# R7FA4E2B9 register map
Vendor: Renesas Electronics Corporation; Series: RA4; File version: 1.30.00
CPU: CM33 r0p4, little endian, MPU, FPU, VTOR, 4 interrupt priority bits, 96 interrupts
Registers are 32-bit, read-write, reset 0x0 unless marked. A register's access mark holds for its fields unless they carry their own. Offsets are from the block's base; [hi:lo] are bit positions; {n}, {i} and the like mark numbered series.

## USBFS — USB 2.0 Full,Speed Module
Base 0x40090000
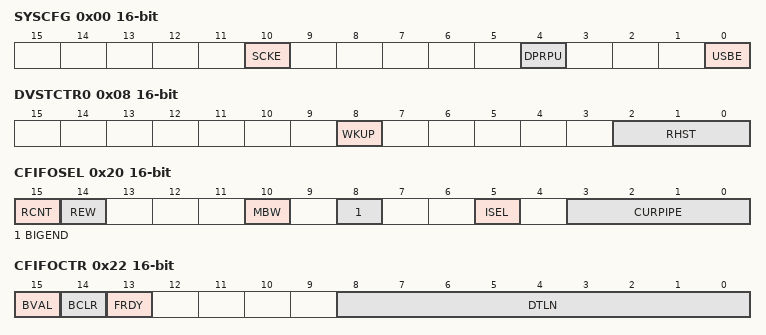
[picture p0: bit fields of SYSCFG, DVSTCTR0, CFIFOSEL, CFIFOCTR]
0x00 SYSCFG 16-bit — System Configuration Control Register
  [10] SCKE — USB Clock Enable
  [4] DPRPU — D+ Line Resistor Control
  [0] USBE — USBFS Operation Enable
0x04 SYSSTS0 16-bit ro — System Configuration Status Register 0
  [1:0] LNST — USB Data Line Status Monitor
0x08 DVSTCTR0 16-bit — Device State Control Register 0
  [8] WKUP — Wakeup Output
  [2:0] RHST ro — USB Bus Reset Status
0x14 CFIFO 16-bit — CFIFO Port Register
  [15:0] FIFOPORT
0x14 CFIFOL 8-bit (alternate view of CFIFO) — CFIFO Port Register
  [7:0] FIFOPORT
0x20 CFIFOSEL 16-bit — CFIFO Port Select Register
  [15] RCNT — Read Count Mode
  [14] REW wo — Buffer Pointer Rewind
  [10] MBW — CFIFO Port Access Bit Width
  [8] BIGEND — CFIFO Port Endian Control
  [5] ISEL — CFIFO Port Access Direction When DCP Is Selected
  [3:0] CURPIPE — CFIFO Port Access Pipe Specification
0x22 CFIFOCTR 16-bit — CFIFO Port Control Register
  [15] BVAL — Buffer Memory Valid Flag
  [14] BCLR wo — CPU Buffer Clear
  [13] FRDY ro — FIFO Port Ready
  [8:0] DTLN ro — Receive Data Length
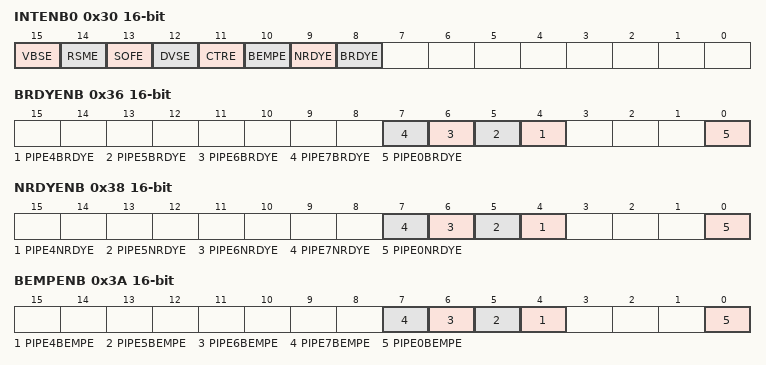
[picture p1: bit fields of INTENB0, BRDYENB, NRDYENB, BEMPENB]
0x30 INTENB0 16-bit — Interrupt Enable Register 0
  [15] VBSE — VBUS Interrupt Enable
  [14] RSME — Resume Interrupt Enable
  [13] SOFE — Frame Number Update Interrupt Enable
  [12] DVSE — Device State Transition Interrupt Enable
  [11] CTRE — Control Transfer Stage Transition Interrupt Enable
  [10] BEMPE — Buffer Empty Interrupt Enable
  [9] NRDYE — Buffer Not Ready Response Interrupt Enable
  [8] BRDYE — Buffer Ready Interrupt Enable
0x36 BRDYENB 16-bit — BRDY Interrupt Enable Register
  [n] PIPE{n}BRDYE (n=4..7) — BRDY Interrupt Enable for Pipe {n}
  [0] PIPE0BRDYE — BRDY Interrupt Enable for Pipe 0
0x38 NRDYENB 16-bit — NRDY Interrupt Enable Register
  [n] PIPE{n}NRDYE (n=4..7) — NRDY Interrupt Enable for Pipe {n}
  [0] PIPE0NRDYE — NRDY Interrupt Enable for Pipe 0
0x3A BEMPENB 16-bit — BEMP Interrupt Enable Register
  [n] PIPE{n}BEMPE (n=4..7) — BEMP Interrupt Enable for Pipe {n}
  [0] PIPE0BEMPE — BEMP Interrupt Enable for Pipe 0
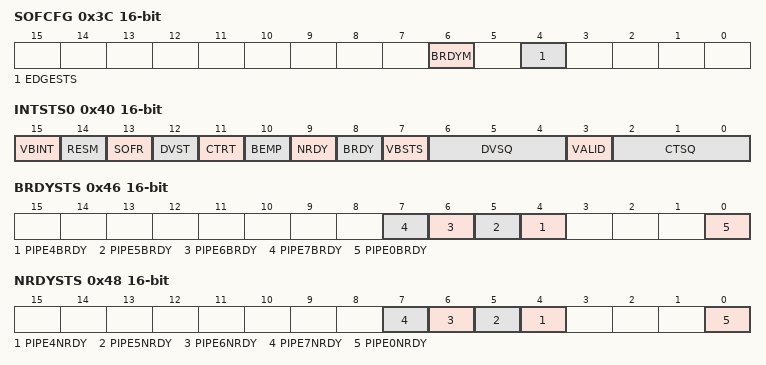
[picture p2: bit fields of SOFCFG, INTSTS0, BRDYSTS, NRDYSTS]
0x3C SOFCFG 16-bit — SOF Output Configuration Register
  [6] BRDYM — BRDY Interrupt Status Clear Timing
  [4] EDGESTS ro — Edge Interrupt Output Status Monitor
0x40 INTSTS0 16-bit (reset mask 0xEF6F) — Interrupt Status Register 0
  [15] VBINT — VBUS Interrupt Status
  [14] RESM — Resume Interrupt Status
  [13] SOFR — Frame Number Refresh Interrupt Status
  [12] DVST — Device State Transition Interrupt Status
  [11] CTRT — Control Transfer Stage Transition Interrupt Status
  [10] BEMP ro — Buffer Empty Interrupt Status
  [9] NRDY ro — Buffer Not Ready Interrupt Status
  [8] BRDY ro — Buffer Ready Interrupt Status
  [7] VBSTS ro — VBUS Input Status
  [6:4] DVSQ ro — Device State
  [3] VALID — USB Request Reception
  [2:0] CTSQ ro — Control Transfer Stage
0x46 BRDYSTS 16-bit — BRDY Interrupt Status Register
  [n] PIPE{n}BRDY (n=4..7) — BRDY Interrupt Status for Pipe {n}
  [0] PIPE0BRDY — BRDY Interrupt Status for Pipe 0
0x48 NRDYSTS 16-bit — NRDY Interrupt Status Register
  [n] PIPE{n}NRDY (n=4..7) — NRDY Interrupt Status for Pipe {n}
  [0] PIPE0NRDY — NRDY Interrupt Status for Pipe 0
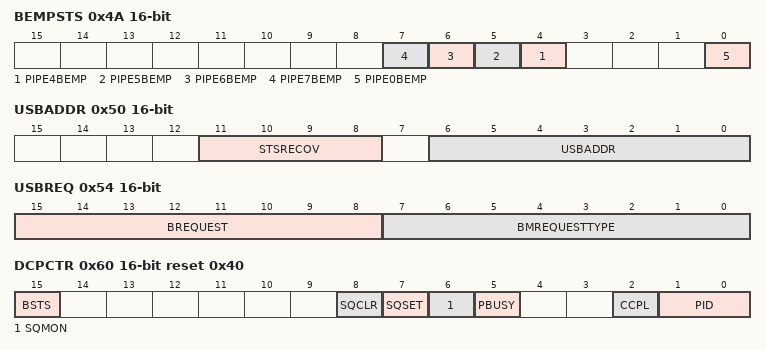
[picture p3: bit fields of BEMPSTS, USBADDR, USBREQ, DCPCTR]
0x4A BEMPSTS 16-bit — BEMP Interrupt Status Register
  [n] PIPE{n}BEMP (n=4..7) — BEMP Interrupt Status for Pipe {n}
  [0] PIPE0BEMP — BEMP Interrupt Status for Pipe 0
0x4C FRMNUM 16-bit ro — Frame Number Register
  [10:0] FRNM — Frame Number
0x4E DVCHGR 16-bit — Device State Change Register
  [15] DVCHG — Device State Change
0x50 USBADDR 16-bit — USB Address Register
  [11:8] STSRECOV — Status Recovery
  [6:0] USBADDR — USB Address
0x54 USBREQ 16-bit ro — USB Request Type Register
  [15:8] BREQUEST — Request
  [7:0] BMREQUESTTYPE — Request Type
0x56 USBVAL 16-bit ro — USB Request Value Register
  [15:0] WVALUE — Value
0x58 USBINDX 16-bit ro — USB Request Index Register
  [15:0] WINDEX — Index
0x5A USBLENG 16-bit ro — USB Request Length Register
  [15:0] WLENTUH — Length
0x5C DCPCFG 16-bit — DCP Configuration Register
  [7] SHTNAK — Pipe Disabled at End of Transfer
0x5E DCPMAXP 16-bit reset 0x40 — DCP Maximum Packet Size Register
  [6:0] MXPS — Maximum Packet Size
0x60 DCPCTR 16-bit reset 0x40 — DCP Control Register
  [15] BSTS ro — Buffer Status
  [8] SQCLR — Sequence Toggle Bit Clear
  [7] SQSET — Sequence Toggle Bit Set
  [6] SQMON ro — Sequence Toggle Bit Monitor
  [5] PBUSY ro — Pipe Busy
  [2] CCPL — Control Transfer End Enable
  [1:0] PID — Response PID
0x64 PIPESEL 16-bit — Pipe Window Select Register
  [3:0] PIPESEL — Pipe Window Select
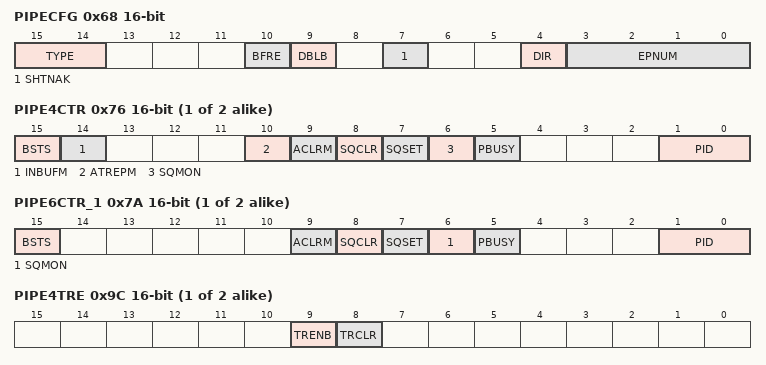
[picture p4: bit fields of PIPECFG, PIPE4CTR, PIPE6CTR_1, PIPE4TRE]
0x68 PIPECFG 16-bit — Pipe Configuration Register
  [15:14] TYPE — Transfer Type
  [10] BFRE — BRDY Interrupt Operation Specification
  [9] DBLB — Double Buffer Mode
  [7] SHTNAK — Pipe Disabled at End of Transfer
  [4] DIR — Transfer Direction
  [3:0] EPNUM — Endpoint Number
0x6C PIPEMAXP 16-bit (reset mask 0xFFBF) — Pipe Maximum Packet Size Register
  [8:0] MXPS — Maximum Packet Size
{0x6E+2i} PIPE{i}CTR (i=4..5) 16-bit — PIPE{i} Control Registers
  [15] BSTS ro — Buffer Status
  [14] INBUFM ro — Transmit Buffer Monitor
  [10] ATREPM — Auto Response Mode
  [9] ACLRM — Auto Buffer Clear Mode
  [8] SQCLR — Sequence Toggle Bit Clear
  [7] SQSET — Sequence Toggle Bit Set
  [6] SQMON ro — Sequence Toggle Bit Confirmation
  [5] PBUSY ro — Pipe Busy
  [1:0] PID — Response PID
{0x6E+2i} PIPE{i}CTR_1 (i=6..7) 16-bit — PIPE{i} Control Registers
  [15] BSTS ro — Buffer Status
  [9] ACLRM — Auto Buffer Clear Mode
  [8] SQCLR wo — Sequence Toggle Bit Clear
  [7] SQSET wo — Sequence Toggle Bit Set
  [6] SQMON ro — Sequence Toggle Bit Confirmation
  [5] PBUSY ro — Pipe Busy
  [1:0] PID — Response PID
{0x8C+4i} PIPE{i}TRE (i=4..5) 16-bit — PIPE{i} Transaction Counter Enable Register
  [9] TRENB — Transaction Counter Enable
  [8] TRCLR — Transaction Counter Clear
{0x8E+4i} PIPE{i}TRN (i=4..5) 16-bit — PIPE{i} Transaction Counter Register
  [15:0] TRNCNT — Transaction Counter
0xF4 PHYSECTRL — PHY Single,ended Receiver Control Register
  [4] CNEN — Single,ended Receiver Enable
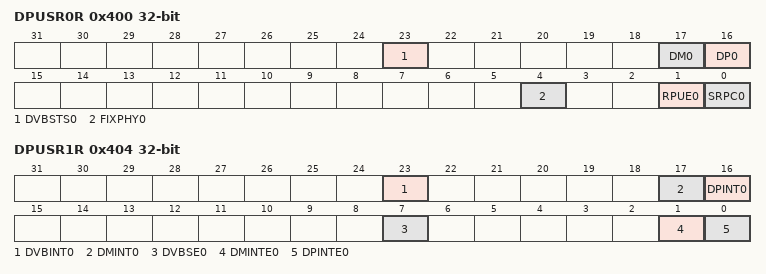
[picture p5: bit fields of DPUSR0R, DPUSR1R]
0x400 DPUSR0R (reset mask 0xFF4CFFFF) — Deep Software Standby USB Transceiver Control/Pin Monitor Register
  [23] DVBSTS0 ro — USB VBUS Input
  [17] DM0 ro — USB D- Input
  [16] DP0 ro — USB D+ Input
  [4] FIXPHY0 — USB Transceiver Output Fix
  [1] RPUE0 — DP Pull,Up Resistor Control
  [0] SRPC0 — USB Single,ended Receiver Control
0x404 DPUSR1R — Deep Software Standby USB Suspend/Resume Interrupt Register
  [23] DVBINT0 ro — USB VBUS Interrupt Source Recovery
  [17] DMINT0 ro — USB DM Interrupt Source Recovery
  [16] DPINT0 ro — USB DP Interrupt Source Recovery
  [7] DVBSE0 — USB VBUS Interrupt Enable/Clear
  [1] DMINTE0 — USB DM Interrupt Enable/Clear
  [0] DPINTE0 — USB DP Interrupt Enable/Clear
